# I94100_v1_3 register map
File version: 1.0
Registers are 32-bit, read-write, reset 0x0 unless marked. A register's access mark holds for its fields unless they carry their own. Offsets are from the block's base; [hi:lo] are bit positions; {n}, {i} and the like mark numbered series; <NAME> marks a mode.

## I2S — I2S Register Map
Base 0x40048000
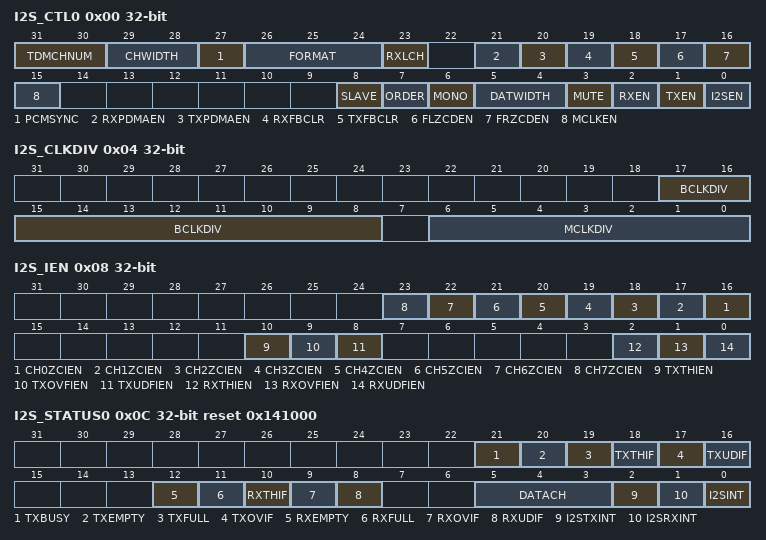
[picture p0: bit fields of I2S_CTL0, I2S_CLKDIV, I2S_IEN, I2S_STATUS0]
0x00 I2S_CTL0 — I2S Control Register 0
  [31:30] TDMCHNUM — TDM Channel Number
    0=2 channels in audio frame; 1=4 channels in audio frame; 2=6 channels in audio frame; 3=8 channels in audio frame
  [29:28] CHWIDTH — Channel Width. This bit fields are used to define the length of audio channel. If CHWIDTH < DATWIDTH, the hardware will set the real channel length as the bit-width of audio data which is defined by DATWIDTH.
    0=The bit-width of each audio channel is 8-bit; 1=The bit-width of each audio channel is 16-bit; 2=The bit-width of each audio channel is 24-bit; 3=The bit-width of each audio channel is 32-bit
  [27] PCMSYNC — PCM Synchronization Pulse Length Selection. This bit field is used to select the high pulse length of frame synchronization signal in PCM protocol. Note: This bit is only available in master mode
    0=One BCLK period; 1=One channel period
  [26:24] FORMAT — Data Format Selection
    0=I2S standard data format; 1=I2S with MSB justified; 2=I2S with LSB justified; 3=Reserved. Do not use; 4=PCM standard data format; 5=PCM with MSB justified; 6=PCM with LSB justified; 7=Reserved. Do not use
  [23] RXLCH — Receive Left Channel Enable Control
    0=Receives channel1 data in MONO mode; 1=Receives channel0 data in MONO mode
  [21] RXPDMAEN — Receive PDMA Enable Control
    0=Receiver PDMA function Disabled; 1=Receiver PDMA function Enabled
  [20] TXPDMAEN — Transmit PDMA Enable Control
    0=Transmit PDMA function Disabled; 1=Transmit PDMA function Enabled
  [19] RXFBCLR — Receive FIFO Buffer Clear. Note1: Write 1 to clear receive FIFO, internal pointer is reset to FIFO start point, and RXCNT (I2S_STATUS1[20:16]) returns 0 and receive FIFO becomes empty. Note2: This bit is cleared by hardware automatically, read it return zero.
    0=No Effect; 1=Clear RX FIFO
  [18] TXFBCLR — Transmit FIFO Buffer Clear. Note1: Write 1 to clear transmit FIFO, internal pointer is reset to FIFO start point, and TXCNT (I2S_STATUS1[12:8]) returns 0 and transmit FIFO becomes empty but data in transmit FIFO is not changed. Note2: This bit is clear by hardware automatically, read it return zero.
    0=No Effect; 1=Clear TX FIFO
  [17] FLZCDEN — Force Left Channel Zero Cross Data Option Bit. If this bit set to 1, when channel (Ch0,Ch2,Ch4,Ch6) data sign bit changes or next shift data bits are all 0 then the channel ZCIF flag in I2S_STATUS1 register is set to 1 and channel data will force zero. This function is only available in transmit operation.
    0=Keep channel (Ch0,Ch2,Ch4,Ch6) data , when zero crossing flag on; 1=Force channel (Ch0,Ch2,Ch4,Ch6) data to zero, when zero crossing flag on
  [16] FRZCDEN — Force Right Channel Zero Cross Data Option Bit. If this bit set to 1, when channel (Ch1,Ch3,Ch5,Ch7) data sign bit changes or next shift data bits are all 0 then the channel ZCIF flag in I2S_STATUS1 register is set to 1 and channel data will force zero. This function is only available in transmit operation.
    0=Keep channel (Ch1,Ch3,Ch5,Ch7) data , when zero crossing flag on; 1=Force channel (Ch1,Ch3,Ch5,Ch7) data to zero, when zero crossing flag on
  [15] MCLKEN — Master Clock Enable Control. If MCLKEN is set to 1, I2S controller will generate master clock on I2S_MCLK pin for external audio devices.
    0=Master clock Disabled; 1=Master clock Enabled
  [8] SLAVE — Slave Mode Enable Control. Note: I2S can operate as master or slave. For Master mode, I2S_BCLK and I2S_LRCLK pins are output mode and send out bit clock to Audio CODEC chip. In Slave mode, I2S_BCLK and I2S_LRCLK pins are input mode and I2S_BCLK and I2S_LRCLK signals are received from outer Audio CODEC chip.
    0=Master mode; 1=Slave mode
  [7] ORDER — Stereo Data Order in FIFO. In 8-bit/16-bit data width, this bit is used to select whether the even or odd channel data is stored in higher byte. In 24-bit data width, this is used to select the left/right alignment method of audio data which is stored in data memory consisted of 32-bit FIFO entries. MSB of 24-bit audio data in each channel is aligned to left side in 32-bit FIFO entries.
    0=Even channel data at high byte in 8-bit/16-bit data width; 1=Even channel data at low byte
  [6] MONO — Monaural Data Control. Note: when chip records data, RXLCH (I2S_CTL0[23]) indicates which channel data will be saved if monaural format is selected.
    0=Data is stereo format; 1=Data is monaural format
  [5:4] DATWIDTH — Data Width. This bit field is used to define the bit-width of data word in each audio channel
    0=The bit-width of data word is 8-bit; 1=The bit-width of data word is 16-bit; 2=The bit-width of data word is 24-bit; 3=The bit-width of data word is 32-bit
  [3] MUTE — Transmit Mute Enable Control
    0=Transmit data is shifted from buffer; 1=Send zero on transmit channel
  [2] RXEN — Receive Enable Control
    0=Data receiving Disabled; 1=Data receiving Enabled
  [1] TXEN — Transmit Enable Control
    0=Data transmission Disabled; 1=Data transmission Enabled
  [0] I2SEN — I2S Controller Enable Control
    0=I2S controller Disabled; 1=I2S controller Enabled
0x04 I2S_CLKDIV — I2S Clock Divider Register
  [17:8] BCLKDIV — Bit Clock Divider. The I2S controller will generate bit clock in Master mode. Software can program these bit fields to generate sampling rate clock frequency. Note: F_BCLK is the frequency of BCLK and F_I2SCLK is the frequency of I2S_CLK
  [6:0] MCLKDIV — Master Clock Divider. If chip external crystal frequency is (2xMCLKDIV)*256fs then software can program these bits to generate 256fs clock frequency to audio codec chip. If MCLKDIV is set to 0, MCLK is the same as external clock input. Note: F_MCLK is the frequency of MCLK, and F_I2SCLK is the frequency of the I2S_CLK
0x08 I2S_IEN — I2S Interrupt Enable Register
  [all] fields
    0=Interrupt Disabled; 1=Interrupt Enabled
  [n+16] CH{n}ZCIEN (n=0..7) — Channel{n} Zero-cross Interrupt Enable Control
  [10] TXTHIEN — Transmit FIFO Threshold Level Interrupt Enable Control. Note: Interrupt occurs if this bit is set to 1 and data words in transmit FIFO is equal to or lower than TXTH (I2S_CTL1[11:8]).
  [9] TXOVFIEN — Transmit FIFO Overflow Interrupt Enable Control. Note: Interrupt occurs if this bit is set to 1 and TXOVIF (I2S_STATUS0[17]) flag is set to 1
  [8] TXUDFIEN — Transmit FIFO Underflow Interrupt Enable Control. Note: Interrupt occur if this bit is set to 1 and TXUDIF (I2S_STATUS0[16]) flag is set to 1.
  [2] RXTHIEN — Receive FIFO Threshold Level Interrupt Enable Control. Note: When data word in receive FIFO is higher than RXTH (I2S_CTL1[19:16]) and the RXTHIF (I2S_STATUS0[10]) bit is set to 1. If RXTHIEN bit is enabled, interrupt occur.
  [1] RXOVFIEN — Receive FIFO Overflow Interrupt Enable Control. Note: Interrupt occurs if this bit is set to 1 and RXOVIF (I2S_STATUS0[9]) flag is set to 1
  [0] RXUDFIEN — Receive FIFO Underflow Interrupt Enable Control. Note: If software reads receive FIFO when it is empty then RXUDIF (I2S_STATUS0[8]) flag is set to 1.
0x0C I2S_STATUS0 reset 0x141000 — I2S Status Register 0
  [21] TXBUSY ro — Transmit Busy (Read Only). Note: This bit is cleared to 0 when all data in transmit FIFO and shift buffer is shifted out. And set to 1 when 1st data is load to shift buffer.
    0=Transmit shift buffer is empty; 1=Transmit shift buffer is busy
  [20] TXEMPTY ro — Transmit FIFO Empty (Read Only). This bit reflect data word number in transmit FIFO is zero
    0=Not empty; 1=Empty
  [19] TXFULL ro — Transmit FIFO Full (Read Only). This bit reflect data word number in transmit FIFO is 16
    0=Not full; 1=Full
  [18] TXTHIF ro — Transmit FIFO Threshold Interrupt Flag (Read Only). Note: When data word(s) in transmit FIFO is equal to or lower than threshold value set in TXTH (I2S_CTL1[11:8]) the TXTHIF bit becomes to 1. It keeps at 1 till TXCNT (I2S_STATUS1[12:8]) is higher than TXTH (I2S_CTL1[11:8]) after software write TXFIFO register.
    0=Data word(s) in FIFO is higher than threshold level; 1=Data word(s) in FIFO is equal or lower than threshold level
  [17] TXOVIF — Transmit FIFO Overflow Interrupt Flag. Note1: Write data to transmit FIFO when it is full and this bit set to 1. Note2: Write 1 to clear this bit to 0.
    0=No overflow; 1=Overflow
  [16] TXUDIF — Transmit FIFO Underflow Interrupt Flag. Note1: This bit will be set to 1 when shift logic hardware read data from transmitting FIFO and the filling data level in transmitting FIFO is not enough for one audio frame. Note2: Write 1 to clear this bit to 0.
    0=No underflow; 1=Underflow
  [12] RXEMPTY ro — Receive FIFO Empty (Read Only). Note: This bit reflects data words number in receive FIFO is zero
    0=Not empty; 1=Empty
  [11] RXFULL ro — Receive FIFO Full (Read Only). Note: This bit reflects data words number in receive FIFO is 16.
    0=Not full; 1=Full
  [10] RXTHIF ro — Receive FIFO Threshold Interrupt Flag (Read Only). Note: When data word(s) in receive FIFO is higher than threshold value set in RXTH (I2S_CTL1[19:16]) the RXTHIF bit becomes to 1. It keeps at 1 till RXCNT (I2S_STATUS1[20:16]) is not higher than RXTH (I2S_CTL1[19:16]) after software read RXFIFO register.
    0=Data word(s) in FIFO is not higher than threshold level; 1=Data word(s) in FIFO is higher than threshold level
  [9] RXOVIF — Receive FIFO Overflow Interrupt Flag. Note1: When receive FIFO is full and receive hardware attempt to write data into receive FIFO then this bit is set to 1, data in 1st buffer is overwrote. Note2: Write 1 to clear this bit to 0.
    0=No overflow occur; 1=Overflow occur
  [8] RXUDIF — Receive FIFO Underflow Interrupt Flag. Note1: When receive FIFO is empty, and software reads the receive FIFO again. This bit will be set to 1, and it indicates underflow situation occurs. Note2: Write 1 to clear this bit to zero
    0=No underflow occur; 1=Underflow occur
  [5:3] DATACH ro — Transmission Data Channel (Read Only). This bit fields are used to indicate which audio channel is current transmit data belong.
    0=channel0 (means left channel while 2-channel I2S/PCM mode); 1=channel1 (means right channel while 2-channel I2S/PCM mode); 2=channel2 (available while 4-channel TDM PCM mode); 3=channel3 (available while 4-channel TDM PCM mode); 4=channel4 (available while 6-channel TDM PCM mode); 5=channel5 (available while 6-channel TDM PCM mode); 6=channel6 (available while 8-channel TDM PCM mode); 7=channel7 (available while 8-channel TDM PCM mode)
  [2] I2STXINT ro — I2S Transmit Interrupt (Read Only)
    0=No transmit interrupt; 1=Transmit interrupt
  [1] I2SRXINT ro — I2S Receive Interrupt (Read Only)
    0=No receive interrupt; 1=Receive interrupt
  [0] I2SINT ro — I2S Interrupt Flag (Read Only). Note: It is wire-OR of I2STXINT and I2SRXINT bits.
    0=No I2S interrupt; 1=I2S interrupt
0x10 I2S_TXFIFO wo — I2S Transmit FIFO Register
  [31:0] TXFIFO — Transmit FIFO Bits. I2S contains 16 words (16x32 bit) data buffer for data transmit. Write data to this register to prepare data for transmit. The remaining word number is indicated by TXCNT (I2S_STATUS1[12:8]).
0x14 I2S_RXFIFO ro — I2S Receive FIFO Register
  [31:0] RXFIFO — Receive FIFO Bits. I2S contains 16 words (16x32 bit) data buffer for data receive. Read this register to get data in FIFO. The remaining data word number is indicated by RXCNT (I2S_STATUS1[20:16]).
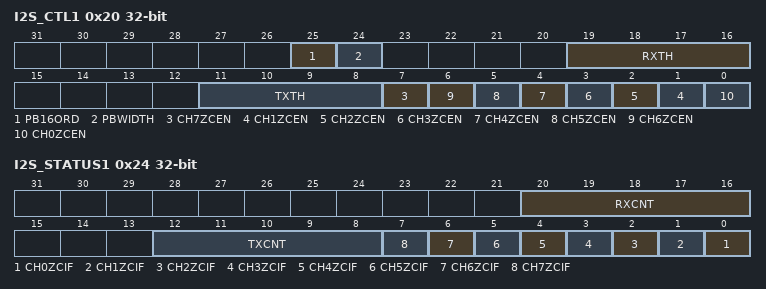
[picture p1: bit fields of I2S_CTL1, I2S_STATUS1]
0x20 I2S_CTL1 — I2S Control Register 1
  [25] PB16ORD — FIFO Read/Write Order in 16-bit Width of Peripheral Bus
    0=Low 16-bit read/write access first; 1=High 16-bit read/write access first
  [24] PBWIDTH — Peripheral Bus Data Width Selection. This bit is used to choice the available data width of APB bus. It must be set to 1 while PDMA function is enable and it is set to 16-bit transmission mode
    0=32 bits data width; 1=16 bits data width
  [19:16] RXTH — Receive FIFO Threshold Level. Note: When received data word number in receive buffer is higher than threshold level then RXTHIF (I2S_STATUS0[10]) flag is set.
    0=1 data word in receive FIFO; 1=2 data words in receive FIFO; 2=3 data words in receive FIFO; 14=15 data words in receive FIFO; 15=16 data words in receive FIFO
  [11:8] TXTH — Transmit FIFO Threshold Level. Note: If remain data word number in transmit FIFO is equal to or lower than threshold level then TXTHIF (I2S_STATUS0[18]) flag is set.
    0=0 data word in transmit FIFO; 1=1 data word in transmit FIFO; 2=2 data words in transmit FIFO; 14=14 data words in transmit FIFO; 15=15 data words in transmit FIFO
  [7] CH7ZCEN — Channel7 Zero-cross Detect Enable Control. Note2: If this bit is set to 1, when channel7 data sign bit change or next shift data bits are all zero then CH7ZCIF (I2S_STATUS1[7]) flag is set to 1. Note3: If CH7ZCIF Flag is set to 1, the channel7 will be mute.
    0=channel7 zero-cross detect Disabled; 1=channel7 zero-cross detect Enabled
  [n] CH{n}ZCEN (n=1..6) — Channel{n} Zero-cross Detect Enable Control. Note2: If this bit is set to 1, when channel{n} data sign bit change or next shift data bits are all zero then CH{n}ZCIF(I2S_STATUS1[{n}]) flag is set to 1. Note3: If CH{n}ZCIF Flag is set to 1, the channel{n} will be mute.
    0=channel{n} zero-cross detect Disabled; 1=channel{n} zero-cross detect Enabled
  [0] CH0ZCEN — Channel0 Zero-cross Detection Enable Control. Note2: If this bit is set to 1, when channel0 data sign bit change or next shift data bits are all zero then CH0ZCIF(I2S_STATUS1[0]) flag is set to 1. Note3: If CH0ZCIF Flag is set to 1, the channel0 will be mute.
    0=channel0 zero-cross detect Disabled; 1=channel0 zero-cross detect Enabled
0x24 I2S_STATUS1 — I2S Status Register 1
  [20:16] RXCNT ro — Receive FIFO Level (Read Only). These bits indicate the number of available entries in receive FIFO. Others are reserved. Do not use.
    0=No data; 1=1 word in receive FIFO; 2=2 words in receive FIFO; 14=14 words in receive FIFO; 15=15 words in receive FIFO; 16=16 words in receive FIFO
  [12:8] TXCNT ro — Transmit FIFO Level (Read Only). These bits indicate the number of available entries in transmit FIFO. Others are reserved. Do not use.
    0=No data; 1=1 word in transmit FIFO; 2=2 words in transmit FIFO; 14=14 words in transmit FIFO; 15=15 words in transmit FIFO; 16=16 words in transmit FIFO
  [n] CH{n}ZCIF (n=0..7) — Channel{n} Zero-cross Interrupt Flag. It indicates channel{n} next sample data sign bit is changed or all data bits are zero.
    0=No zero-cross in channel{n}; 1=Channel{n} zero-cross is detected
